# STM32F411 register map
File version: 1.9
CPU: CM4 r0p1, little endian, MPU, FPU, 4 interrupt priority bits
Registers are 32-bit, read-write, reset 0x0 unless marked. A register's access mark holds for its fields unless they carry their own. Offsets are from the block's base; [hi:lo] are bit positions; {n}, {i} and the like mark numbered series.

## ADC_Common — ADC common registers
Base 0x40012300
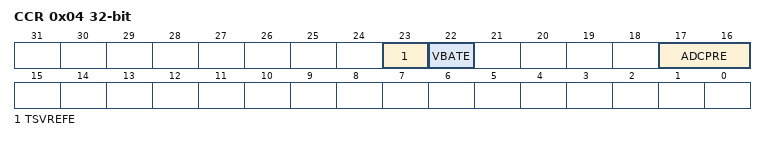
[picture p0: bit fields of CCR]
0x04 CCR — ADC common control register
  [23] TSVREFE — Temperature sensor and VREFINT enable
    0=Disabled (Temperature sensor and V_REFINT channel disabled); 1=Enabled (Temperature sensor and V_REFINT channel enabled)
  [22] VBATE — VBAT enable
    0=Disabled (V_BAT channel disabled); 1=Enabled (V_BAT channel enabled)
  [17:16] ADCPRE — ADC prescaler
    0=Div2 (PCLK2 divided by 2); 1=Div4 (PCLK2 divided by 4); 2=Div6 (PCLK2 divided by 6); 3=Div8 (PCLK2 divided by 8)

## CRC — Cryptographic processor
Base 0x40023000
0x00 DR reset 0xFFFFFFFF — Data register
  [31:0] DR — Data Register
0x04 IDR — Independent Data register
  [7:0] IDR
0x08 CR wo — Control register
  [0] RESET — Control regidter
    1=Resets the CRC calculation unit and sets the data register to 0xFFFF FFFF

## DBGMCU — Debug support
Base 0xE0042000
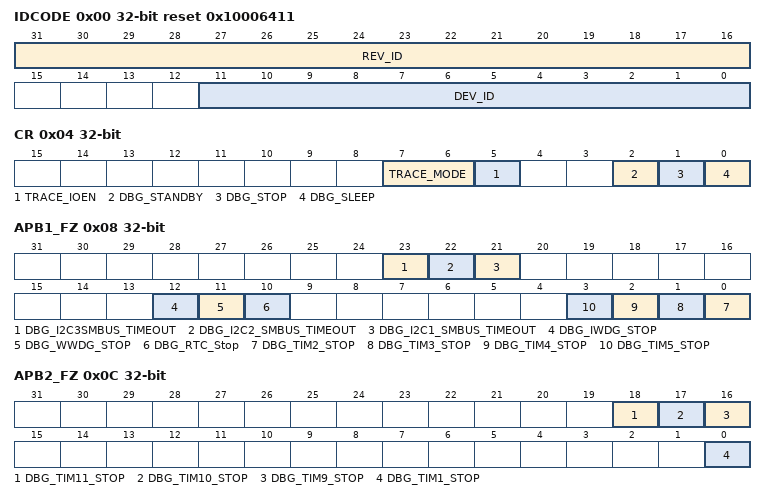
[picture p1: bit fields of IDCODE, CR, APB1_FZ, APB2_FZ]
0x00 IDCODE ro reset 0x10006411
  [31:16] REV_ID, [11:0] DEV_ID
0x04 CR — Control Register
  [7:6] TRACE_MODE, [5] TRACE_IOEN, [2] DBG_STANDBY, [1] DBG_STOP, [0] DBG_SLEEP
0x08 APB1_FZ — Debug MCU APB1 Freeze registe
  [23] DBG_I2C3SMBUS_TIMEOUT — DBG_J2C3SMBUS_TIMEOUT
  [22] DBG_I2C2_SMBUS_TIMEOUT — DBG_J2C2_SMBUS_TIMEOUT
  [21] DBG_I2C1_SMBUS_TIMEOUT — DBG_J2C1_SMBUS_TIMEOUT
  [12] DBG_IWDG_STOP — DBG_IWDEG_STOP
  [11] DBG_WWDG_STOP
  [10] DBG_RTC_Stop — RTC stopped when Core is halted
  [n-2] DBG_TIM{n}_STOP (n=2..5)
0x0C APB2_FZ — Debug MCU APB2 Freeze registe
  [18] DBG_TIM11_STOP — TIM11 counter stopped when core is halted
  [17] DBG_TIM10_STOP — TIM10 counter stopped when core is halted
  [16] DBG_TIM9_STOP — TIM9 counter stopped when core is halted
  [0] DBG_TIM1_STOP — TIM1 counter stopped when core is halted

## EXTI — External interrupt/event controller
Base 0x40013C00
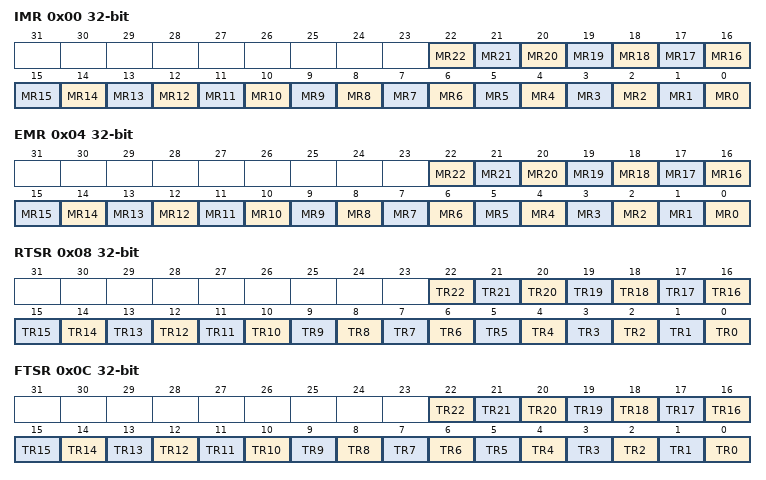
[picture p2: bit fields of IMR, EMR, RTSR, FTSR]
0x00 IMR — Interrupt mask register (EXTI_IMR)
  [n] MR{n} (n=0..22) — Interrupt Mask on line {n}
    0=Masked (Interrupt request line is masked); 1=Unmasked (Interrupt request line is unmasked)
0x04 EMR — Event mask register (EXTI_EMR)
  [n] MR{n} (n=0..22) — Event Mask on line {n}
    0=Masked (Event request line is masked); 1=Unmasked (Event request line is unmasked)
0x08 RTSR — Rising Trigger selection register (EXTI_RTSR)
  [n] TR{n} (n=0..22) — Rising trigger event configuration of line {n}
    0=Disabled (Rising edge trigger is disabled); 1=Enabled (Rising edge trigger is enabled)
0x0C FTSR — Falling Trigger selection register (EXTI_FTSR)
  [n] TR{n} (n=0..22) — Falling trigger event configuration of line {n}
    0=Disabled (Falling edge trigger is disabled); 1=Enabled (Falling edge trigger is enabled)
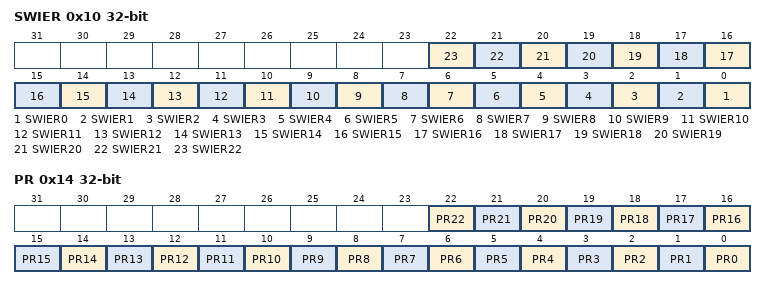
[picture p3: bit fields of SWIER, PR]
0x10 SWIER — Software interrupt event register (EXTI_SWIER)
  [n] SWIER{n} (n=0..22) — Software Interrupt on line {n}
    on write: 1=Pend (Generates an interrupt request)
0x14 PR — Pending register (EXTI_PR)
  [n] PR{n} (n=0..22) write-1-clears — Pending bit {n}
    on read: 0=NotPending (No trigger request occurred); 1=Pending (Selected trigger request occurred) | on write: 1=Clears pending bit

## IWDG — Independent watchdog
Base 0x40003000
0x00 KR 16-bit wo — Key register
  [15:0] KEY — Key value
    0x5555=Unlock (Enable access to PR, RLR and WINR registers); 0xAAAA=Feed watchdog with RLR register value; 0xCCCC=Start the watchdog
0x04 PR 16-bit — Prescaler register
  [2:0] PR — Prescaler divider
    0=DivideBy4 (Divider /4); 1=DivideBy8 (Divider /8); 2=DivideBy16 (Divider /16); 3=DivideBy32 (Divider /32); 4=DivideBy64 (Divider /64); 5=DivideBy128 (Divider /128); other=DivideBy256 (Divider /256)
0x08 RLR 16-bit reset 0xFFF — Reload register
  [11:0] RL — Watchdog counter reload value
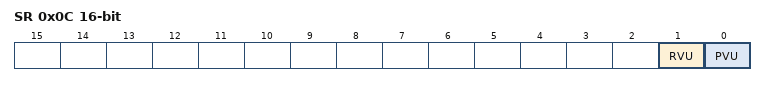
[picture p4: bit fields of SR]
0x0C SR 16-bit ro — Status register
  [1] RVU — Watchdog counter reload value update
  [0] PVU — Watchdog prescaler value update
